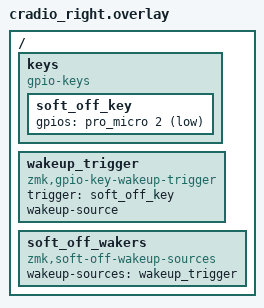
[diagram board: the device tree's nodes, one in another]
/*
 * Right half soft off wakeup configuration.
 * Only the / key (pro_micro 2) can wake this half from soft off.
 *
 * No need to remove wakeup-source from kscan0 — ZMK's soft off code
 * disables all wakeup sources first, then enables only soft_off_wakers.
 * The kscan0 wakeup-source still handles idle sleep wake (desired).
 */

/ {
    keys {
        compatible = "gpio-keys";
        soft_off_key: soft_off_key {
            gpios = <&pro_micro 2 (GPIO_ACTIVE_LOW | GPIO_PULL_UP)>;
        };
    };

    wakeup_trigger: wakeup_trigger {
        compatible = "zmk,gpio-key-wakeup-trigger";
        trigger = <&soft_off_key>;
        wakeup-source;
    };

    soft_off_wakers {
        compatible = "zmk,soft-off-wakeup-sources";
        wakeup-sources = <&wakeup_trigger>;
    };
};
